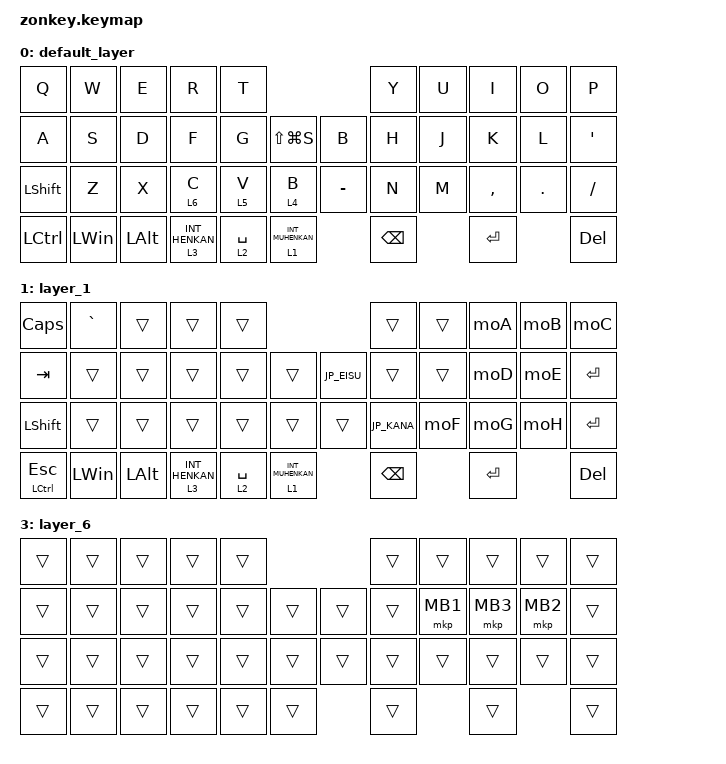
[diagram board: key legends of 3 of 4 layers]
#include <behaviors.dtsi>
#include <dt-bindings/zmk/bt.h>
#include <dt-bindings/zmk/keys.h>
#include <dt-bindings/zmk/pointing.h>

/* -------------------------------------------------
 * Global defines
 * ------------------------------------------------- */
#define ZMK_POINTING_DEFAULT_SCRL_VAL 100
#define MOUSE 6

/* JIS helpers */
#define JP_DQUOTE       AT
#define JP_AMPERSAND    CARET
#define JP_QUOTE        AMPERSAND
#define JP_EQUAL        UNDER
#define JP_CARET        EQUAL
#define JP_YEN          0x89
#define JP_PLUS         COLON
#define JP_TILDE        PLUS
#define JP_PIPE         LS(0x89)
#define JP_AT           LEFT_BRACKET
#define JP_COLON        SINGLE_QUOTE
#define JP_ASTERISK     DOUBLE_QUOTES
#define JP_BACKQUOTE    LEFT_BRACE
#define JP_UNDERSCORE   LS(0x87)
#define JP_LBRACKET     RIGHT_BRACKET
#define JP_RBRACKET     BACKSLASH
#define JP_LPAREN       ASTERISK
#define JP_RPAREN       LEFT_PARENTHESIS
#define JP_LBRACE       RIGHT_BRACE
#define JP_RBRACE       PIPE
#define JP_KANA         LANGUAGE_1
#define JP_EISU         LANGUAGE_2
#define JP_HANZEN       GRAVE
#define JP_BSLH         INT1

/* -------------------------------------------------
 * Hold-tap tuning
 * ------------------------------------------------- */
&mt {
    flavor = "balanced";
    quick-tap-ms = <0>;
};

/* -------------------------------------------------
 * Root
 * ------------------------------------------------- */
 / {
    combos { compatible = "zmk,combos"; };

    /* ---------- mod-morph numbers ---------- */
    mo2: mo2 { compatible = "zmk,behavior-mod-morph"; #binding-cells = <0>; bindings = <&kp N2>, <&kp AT>;    mods = <(MOD_LSFT|MOD_RSFT)>; };
    mo6: mo6 { compatible = "zmk,behavior-mod-morph"; #binding-cells = <0>; bindings = <&kp N6>, <&kp CARET>; mods = <(MOD_LSFT|MOD_RSFT)>; };
    mo7: mo7 { compatible = "zmk,behavior-mod-morph"; #binding-cells = <0>; bindings = <&kp N7>, <&kp AMPS>;  mods = <(MOD_LSFT|MOD_RSFT)>; };
    mo8: mo8 { compatible = "zmk,behavior-mod-morph"; #binding-cells = <0>; bindings = <&kp N8>, <&kp ASTRK>; mods = <(MOD_LSFT|MOD_RSFT)>; };
    mo9: mo9 { compatible = "zmk,behavior-mod-morph"; #binding-cells = <0>; bindings = <&kp N9>, <&kp LPAR>;  mods = <(MOD_LSFT|MOD_RSFT)>; };
    mo0: mo0 { compatible = "zmk,behavior-mod-morph"; #binding-cells = <0>; bindings = <&kp N0>, <&kp LS(N9)>;mods = <(MOD_LSFT|MOD_RSFT)>; };

    moA: moA { compatible = "zmk,behavior-mod-morph"; #binding-cells = <0>; bindings = <&kp MINUS>, <&kp UNDERSCORE>; mods = <(MOD_LSFT|MOD_RSFT)>; };
    moB: moB { compatible = "zmk,behavior-mod-morph"; #binding-cells = <0>; bindings = <&kp EQUAL>, <&kp PLUS>;      mods = <(MOD_LSFT|MOD_RSFT)>; };
    moC: moC { compatible = "zmk,behavior-mod-morph"; #binding-cells = <0>; bindings = <&kp INT3>, <&kp JP_PIPE>;   mods = <(MOD_LSFT|MOD_RSFT)>; };
    moD: moD { compatible = "zmk,behavior-mod-morph"; #binding-cells = <0>; bindings = <&kp LBKT>, <&kp LBRC>;      mods = <(MOD_LSFT|MOD_RSFT)>; };
    moE: moE { compatible = "zmk,behavior-mod-morph"; #binding-cells = <0>; bindings = <&kp RBKT>, <&kp RBRC>;      mods = <(MOD_LSFT|MOD_RSFT)>; };
    moF: moF { compatible = "zmk,behavior-mod-morph"; #binding-cells = <0>; bindings = <&kp SEMI>, <&kp KP_PLUS>;  mods = <(MOD_LSFT|MOD_RSFT)>; };
    moG: moG { compatible = "zmk,behavior-mod-morph"; #binding-cells = <0>; bindings = <&kp APOSTROPHE>, <&kp DQT>;mods = <(MOD_LSFT|MOD_RSFT)>; };
    moH: moH { compatible = "zmk,behavior-mod-morph"; #binding-cells = <0>; bindings = <&kp BACKSLASH>, <&kp TILDE2>; mods = <(MOD_LSFT|MOD_RSFT)>; };
    moI: moI { compatible = "zmk,behavior-mod-morph"; #binding-cells = <0>; bindings = <&kp JP_BSLH>, <&kp JP_UNDERSCORE>; mods = <(MOD_LSFT|MOD_RSFT)>; };

    /* ---------- macros ---------- */
    macros {
        to_layer_0: to_layer_0 {
            compatible = "zmk,behavior-macro-one-param";
            #binding-cells = <1>;
            bindings = <&to 0 &macro_param_1to1 &kp MACRO_PLACEHOLDER>;
        };
    };

    /* ---------- behaviors ---------- */
    behaviors {
        lt_to_layer_0: lt_to_layer_0 {
            compatible = "zmk,behavior-hold-tap";
            bindings = <&mo>, <&to_layer_0>;
            #binding-cells = <2>;
            tapping-term-ms = <200>;
        };

        scroll_up_down: behavior_sensor_rotate_mouse_wheel_up_down {
            compatible = "zmk,behavior-sensor-rotate";
            #sensor-binding-cells = <0>;
            bindings = <&msc SCRL_DOWN>, <&msc SCRL_UP>;
            tap-ms = <20>;
        };
    };

    /* -------------------------------------------------
     * Keymap
     * ------------------------------------------------- */
    keymap {
        compatible = "zmk,keymap";

        /* ===== LAYER 0 ===== */
        default_layer {
            bindings = <
                &kp Q           &kp W         &kp E         &kp R         &kp T                         &kp Y     &kp U     &kp I     &kp O     &kp P
                &kp A           &kp S         &kp D         &kp F         &kp G     &kp LS(LG(S)) &kp B   &kp H     &kp J     &kp K     &kp L     &kp SQT
                &kp LEFT_SHIFT  &kp Z         &kp X         &lt 6 C       &lt 5 V   &lt 4 B       &kp MINUS &kp N     &kp M     &kp COMMA &kp DOT   &kp SLASH
                &kp LCTRL       &kp LEFT_WIN  &kp LEFT_ALT  &lt 3 INT_HENKAN &lt 2 SPACE &lt 1 INT_MUHENKAN   &kp BACKSPACE &kp ENTER             &kp DEL
            >;
            sensor-bindings = <&inc_dec_kp RIGHT_ARROW LEFT_ARROW &scroll_up_down>;
        };

        /* ===== LAYER 1 ===== */
        layer_1 {
            bindings = <
                &kp CAPSLOCK &kp GRAVE &trans &trans &trans              &trans &trans &moA &moB &moC
                &kp TAB      &trans    &trans &trans &trans              &trans &kp JP_EISU &trans &trans &moD &moE &kp ENTER
                &kp LEFT_SHIFT &trans  &trans &trans &trans              &trans &trans &kp JP_KANA &moF &moG &moH &kp ENTER
                &mt LCTL ESC &kp LEFT_WIN &kp LEFT_ALT &lt 3 INT_HENKAN &lt 2 SPACE &lt 1 INT_MUHENKAN &kp BACKSPACE &kp ENTER &kp DEL
            >;
            sensor-bindings = <&inc_dec_kp RIGHT_ARROW LEFT_ARROW &scroll_up_down>;
        };

        /* ===== LAYER 2 ===== */
        layer_2 {
            bindings = <
                &kp N1 &mo2 &kp N3 &kp N4 &kp N5     &mo6 &mo7 &mo8 &mo9 &mo0
                &trans &trans &trans &trans &trans   &trans &trans &trans &trans &kp UP_ARROW &trans
                &kp LEFT_SHIFT &trans &trans &trans &trans &trans &trans &trans &trans &kp LEFT_ARROW &kp DOWN_ARROW &kp RIGHT_ARROW
                &kp LCTRL &kp LEFT_WIN &kp LEFT_ALT &lt 3 INT_HENKAN &lt 2 SPACE &lt 1 INT_MUHENKAN &kp BACKSPACE &kp ENTER &kp DEL
            >;
            sensor-bindings = <&inc_dec_kp RIGHT_ARROW LEFT_ARROW &scroll_up_down>;
        };

        /* ===== LAYER 6 (MOUSE) ===== */
        layer_6 {
            bindings = <
                &trans &trans &trans &trans &trans        &trans &trans &trans &trans &trans
                &trans &trans &trans &trans &trans &trans &trans &trans &mkp MB1 &mkp MB3 &mkp MB2 &trans
                &trans &trans &trans &trans &trans &trans &trans &trans &trans &trans &trans &trans
                &trans &trans &trans &trans &trans &trans &trans &trans &trans
            >;
            sensor-bindings = <&inc_dec_kp RIGHT_ARROW LEFT_ARROW &scroll_up_down>;
        };
    };
};
